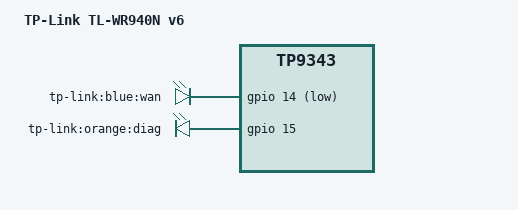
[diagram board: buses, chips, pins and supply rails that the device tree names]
// SPDX-License-Identifier: GPL-2.0-or-later OR MIT
/dts-v1/;

#include "tp9343_tplink_tl-wr94x.dtsi"

/ {
	compatible = "tplink,tl-wr940n-v6", "qca,tp9343";
	model = "TP-Link TL-WR940N v6";

	leds {
		compatible = "gpio-leds";

		wan_blue {
			label = "tp-link:blue:wan";
			gpios = <&gpio 14 GPIO_ACTIVE_LOW>;
		};

		diag_orange {
			label = "tp-link:orange:diag";
			gpios = <&gpio 15 GPIO_ACTIVE_HIGH>;
		};
	};
};

&eth1 {
	mtd-mac-address = <&uboot 0x1fc00>;
};
